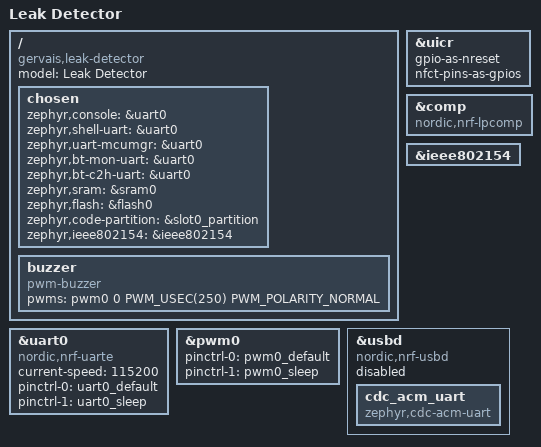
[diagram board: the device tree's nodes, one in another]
/dts-v1/;
#include <nordic/nrf52840_qiaa.dtsi>
#include "leak_detector-pinctrl.dtsi"

/ {
	model = "Leak Detector";
	compatible = "gervais,leak-detector";

	chosen {
		zephyr,console = &uart0;
		zephyr,shell-uart = &uart0;
		zephyr,uart-mcumgr = &uart0;
		zephyr,bt-mon-uart = &uart0;
		zephyr,bt-c2h-uart = &uart0;
		// zephyr,console = &cdc_acm_uart;
		// zephyr,shell-uart = &cdc_acm_uart;
		// zephyr,uart-mcumgr = &cdc_acm_uart;
		// zephyr,bt-mon-uart = &cdc_acm_uart;
		// zephyr,bt-c2h-uart = &cdc_acm_uart;
		zephyr,sram = &sram0;
		zephyr,flash = &flash0;
		zephyr,code-partition = &slot0_partition;
		zephyr,ieee802154 = &ieee802154;
	};

	buzzer {
		compatible = "pwm-buzzer";
		pwms = <&pwm0 0 PWM_USEC(250) PWM_POLARITY_NORMAL>;
	};
};

&uicr {
	gpio-as-nreset;
	nfct-pins-as-gpios;
};

&uart0 {
	compatible = "nordic,nrf-uarte";
	status = "okay";
	current-speed = <115200>;
	pinctrl-0 = <&uart0_default>;
	pinctrl-1 = <&uart0_sleep>;
	pinctrl-names = "default", "sleep";
};

&comp {
	compatible = "nordic,nrf-lpcomp";
	status = "okay";
};

&pwm0 {
	status = "okay";
	pinctrl-0 = <&pwm0_default>;
	pinctrl-1 = <&pwm0_sleep>;
	pinctrl-names = "default", "sleep";
};

&ieee802154 {
	status = "okay";
};

/* Include flash partition table.
 * Two partition tables are available:
 * fstab-stock		-compatible with Nordic nRF5 bootloader, default
 * fstab-debugger	-to use an external debugger, w/o the nRF5 bootloader
 */
#include "fstab-debugger.dts"

zephyr_udc0: &usbd {
	compatible = "nordic,nrf-usbd";
	status = "disabled";

	cdc_acm_uart: cdc_acm_uart {
		compatible = "zephyr,cdc-acm-uart";
	};
};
